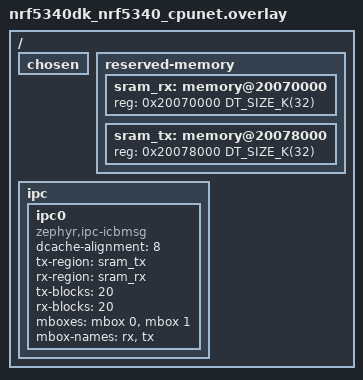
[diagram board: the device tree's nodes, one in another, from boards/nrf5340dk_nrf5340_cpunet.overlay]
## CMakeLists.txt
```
# Copyright (c) 2026 Nordic Semiconductor ASA
# SPDX-License-Identifier: Apache-2.0

cmake_minimum_required(VERSION 3.28.0)
find_package(Zephyr REQUIRED HINTS $ENV{ZEPHYR_BASE})
project(log_ipc_remote)

target_sources(app PRIVATE src/main.c)
```

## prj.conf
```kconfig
CONFIG_IPC_SERVICE=y
CONFIG_MBOX=y
CONFIG_IPC_SERVICE_LOG_LEVEL_OFF=y

CONFIG_SHELL=y
CONFIG_SHELL_REMOTE_CLI=y
CONFIG_SHELL_BACKEND_SERIAL=n
CONFIG_SHELL_LOG_BACKEND=n

# Logging method (IPC frontend or IPC backend) is selected by sysbuild.
CONFIG_LOG=y
CONFIG_LOG_MODE_DEFERRED=y
CONFIG_LOG_FUNC_NAME_PREFIX_DBG=n
CONFIG_LOG_PRINTK=n
CONFIG_LOG_BACKEND_UART=n
CONFIG_LOG_BACKEND_NATIVE_POSIX=n
CONFIG_LOG_BACKEND_RTT=n
CONFIG_LOG_RUNTIME_FILTERING=n

CONFIG_BOOT_BANNER=n
CONFIG_GPIO=n

CONFIG_OUTPUT_DISASSEMBLY=y
```

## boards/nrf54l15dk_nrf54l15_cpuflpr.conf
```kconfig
# CPUFLPR has limited RAM.
CONFIG_CBPRINTF_CONVERT_CHECK_PTR=n
#CONFIG_SERIAL=n
#CONFIG_CONSOLE=n
#CONFIG_UART_CONSOLE=n
#CONFIG_PRINTK=n
```

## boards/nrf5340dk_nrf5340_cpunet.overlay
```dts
/*
 * Copyright (c) 2026 Nordic Semiconductor ASA
 *
 * SPDX-License-Identifier: Apache-2.0
 */

/delete-node/ &ipc0;
/delete-node/ &sram0_shared;

/ {
	chosen {
		/delete-property/ zephyr,ipc_shm;
	};

	reserved-memory {
		ranges;
		#address-cells = <1>;
		#size-cells = <1>;

		sram_rx: memory@20070000 {
			reg = <0x20070000 DT_SIZE_K(32)>;
		};

		sram_tx: memory@20078000 {
			reg = <0x20078000 DT_SIZE_K(32)>;
		};
	};

	ipc {
		ipc0: ipc0 {
			compatible = "zephyr,ipc-icbmsg";
			dcache-alignment = <8>;
			tx-region = <&sram_tx>;
			rx-region = <&sram_rx>;
			tx-blocks = <20>;
			rx-blocks = <20>;
			mboxes = <&mbox 0>, <&mbox 1>;
			mbox-names = "rx", "tx";
			status = "okay";
		};
	};
};
```

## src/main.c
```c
/*
 * Copyright (c) 2026 Nordic Semiconductor ASA
 *
 * SPDX-License-Identifier: Apache-2.0
 */

#include <zephyr/kernel.h>
#include <zephyr/init.h>
#include <zephyr/shell/shell.h>
#include <zephyr/shell/shell_remote_cli.h>
#include <zephyr/logging/log_ctrl.h>
#include <zephyr/logging/log.h>
#include <stdlib.h>

/* Messages are checked by the test running on the application core. */
LOG_MODULE_REGISTER(remote, LOG_LEVEL_DBG);

#define EARLY_LOG_CNT 3

/* Runs before IPC is initialized so messages are created before the endpoint is bound. */
static int early_log(void)
{
	for (int i = 0; i < EARLY_LOG_CNT; i++) {
		LOG_INF("early %d/%d", i, EARLY_LOG_CNT);
	}

	return 0;
}

SYS_INIT(early_log, PRE_KERNEL_2, 0);

static int cmd_levels(const struct shell *sh, size_t argc, char **argv)
{
	ARG_UNUSED(argc);
	ARG_UNUSED(argv);
	char rw_str[] = "rw_str";
	static const uint8_t data[] = {0xde, 0xad, 0xbe, 0xef, 0x01, 0x02, 0x03, 0x04};

	LOG_ERR("lvl err %d", -1);
	LOG_WRN("lvl wrn %s", "ro_str");
	LOG_INF("lvl inf %s", rw_str);
	LOG_DBG("lvl dbg %d %lld", 100, 0x1234567890LL);
	LOG_HEXDUMP_INF(data, sizeof(data), "lvl hexdump");
	/* Marks that all previous messages were processed. */
	LOG_ERR("lvl end");

	shell_print(sh, "done");
	return 0;
}

static int cmd_burst(const struct shell *sh, size_t argc, char **argv)
{
	int cnt = (int)strtol(argv[1], NULL, 10);

	for (int i = 0; i < cnt; i++) {
		LOG_INF("burst %d", i);
	}

	shell_print(sh, "done");
	return 0;
}

static int cmd_kernel_panic(const struct shell *sh, size_t argc, char **argv)
{
	ARG_UNUSED(argc);
	ARG_UNUSED(argv);

	printk("panic\n");
	k_panic();

	return 0;
}

SHELL_CMD_REGISTER(panic, NULL, "Please, panic now!", cmd_kernel_panic);

SHELL_STATIC_SUBCMD_SET_CREATE(
	sub_log_gen,
	SHELL_CMD_ARG(levels, NULL, "Log a message on each level and a hexdump", cmd_levels, 1, 0),
	SHELL_CMD_ARG(burst, NULL, "<count> Log count messages", cmd_burst, 2, 0),
	SHELL_SUBCMD_SET_END);

SHELL_CMD_REGISTER(log_gen, &sub_log_gen, "Generate log messages", NULL);

int main(void)
{
#ifndef CONFIG_MULTITHREADING
	while (1) {
		shell_remote_cmd_process();
		if (LOG_PROCESS() == false) {
			k_cpu_idle();
		}
	}
#endif
	return 0;
}
```
